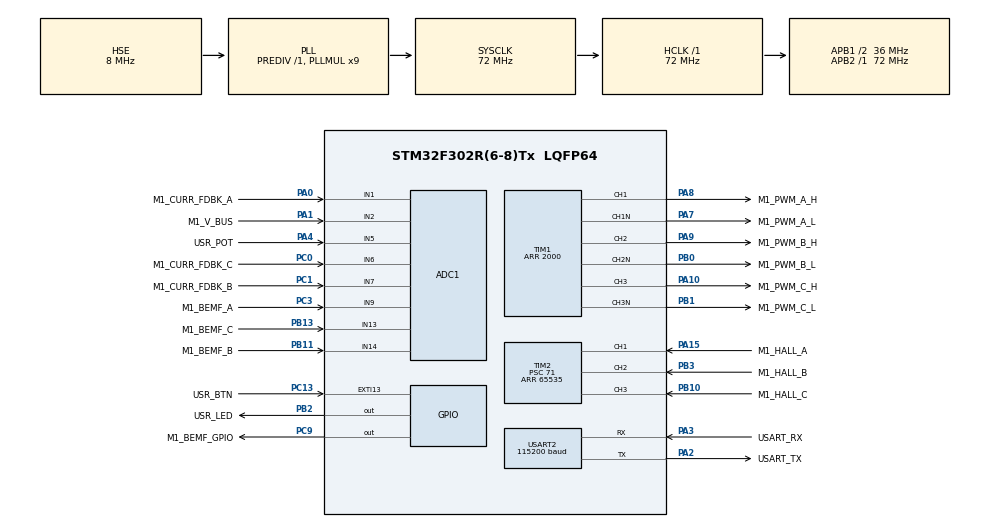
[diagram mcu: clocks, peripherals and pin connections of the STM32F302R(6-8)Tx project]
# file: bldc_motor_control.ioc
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ADC1.Channel-1\#ChannelRegularConversion=ADC_CHANNEL_9
ADC1.Channel-12\#ChannelRegularConversion=ADC_CHANNEL_6
ADC1.Channel-13\#ChannelRegularConversion=ADC_CHANNEL_2
ADC1.Channel-14\#ChannelRegularConversion=ADC_CHANNEL_5
ADC1.Channel-2\#ChannelRegularConversion=ADC_CHANNEL_14
ADC1.Channel-3\#ChannelRegularConversion=ADC_CHANNEL_13
ADC1.Channel-4\#ChannelRegularConversion=ADC_CHANNEL_1
ADC1.Channel-5\#ChannelRegularConversion=ADC_CHANNEL_7
ADC1.DMAContinuousRequests=ENABLE
ADC1.EOCSelection=ADC_EOC_SEQ_CONV
ADC1.EnableInjectedConversion=DISABLE
ADC1.ExternalTrigConv=ADC_EXTERNALTRIGCONV_T1_TRGO
ADC1.NbrOfConversion=8
ADC1.NbrOfConversionFlag=1
ADC1.Offset-1\#ChannelRegularConversion=0
ADC1.Offset-12\#ChannelRegularConversion=0
ADC1.Offset-13\#ChannelRegularConversion=0
ADC1.Offset-14\#ChannelRegularConversion=0
ADC1.Offset-2\#ChannelRegularConversion=0
ADC1.Offset-3\#ChannelRegularConversion=0
ADC1.Offset-4\#ChannelRegularConversion=0
ADC1.Offset-5\#ChannelRegularConversion=0
ADC1.OffsetNumber-1\#ChannelRegularConversion=ADC_OFFSET_NONE
ADC1.OffsetNumber-12\#ChannelRegularConversion=ADC_OFFSET_NONE
ADC1.OffsetNumber-13\#ChannelRegularConversion=ADC_OFFSET_NONE
ADC1.OffsetNumber-14\#ChannelRegularConversion=ADC_OFFSET_NONE
ADC1.OffsetNumber-2\#ChannelRegularConversion=ADC_OFFSET_NONE
ADC1.OffsetNumber-3\#ChannelRegularConversion=ADC_OFFSET_NONE
ADC1.OffsetNumber-4\#ChannelRegularConversion=ADC_OFFSET_NONE
ADC1.OffsetNumber-5\#ChannelRegularConversion=ADC_OFFSET_NONE
ADC1.Rank-1\#ChannelRegularConversion=1
ADC1.Rank-12\#ChannelRegularConversion=6
ADC1.Rank-13\#ChannelRegularConversion=7
ADC1.Rank-14\#ChannelRegularConversion=8
ADC1.Rank-2\#ChannelRegularConversion=2
ADC1.Rank-3\#ChannelRegularConversion=3
ADC1.Rank-4\#ChannelRegularConversion=4
ADC1.Rank-5\#ChannelRegularConversion=5
ADC1.Rank1_Channel=ADC_CHANNEL_9
ADC1.Rank2_Channel=ADC_CHANNEL_13
ADC1.Rank3_Channel=ADC_CHANNEL_14
ADC1.SamplingTime-1\#ChannelRegularConversion=ADC_SAMPLETIME_61CYCLES_5
ADC1.SamplingTime-12\#ChannelRegularConversion=ADC_SAMPLETIME_61CYCLES_5
ADC1.SamplingTime-13\#ChannelRegularConversion=ADC_SAMPLETIME_61CYCLES_5
ADC1.SamplingTime-14\#ChannelRegularConversion=ADC_SAMPLETIME_61CYCLES_5
ADC1.SamplingTime-2\#ChannelRegularConversion=ADC_SAMPLETIME_61CYCLES_5
ADC1.SamplingTime-3\#ChannelRegularConversion=ADC_SAMPLETIME_61CYCLES_5
ADC1.SamplingTime-4\#ChannelRegularConversion=ADC_SAMPLETIME_61CYCLES_5
ADC1.SamplingTime-5\#ChannelRegularConversion=ADC_SAMPLETIME_61CYCLES_5
ADC1.SamplingTimeOPAMP-12\#ChannelRegularConversion=ADC_SAMPLETIME_61CYCLES_5
ADC1.SamplingTimeOPAMP-13\#ChannelRegularConversion=ADC_SAMPLETIME_61CYCLES_5
ADC1.SamplingTimeOPAMP-14\#ChannelRegularConversion=ADC_SAMPLETIME_61CYCLES_5
ADC1.SamplingTimeOPAMP-2\#ChannelRegularConversion=ADC_SAMPLETIME_61CYCLES_5
ADC1.SamplingTimeOPAMP-3\#ChannelRegularConversion=ADC_SAMPLETIME_61CYCLES_5
ADC1.SamplingTimeOPAMP-4\#ChannelRegularConversion=ADC_SAMPLETIME_61CYCLES_5
ADC1.SamplingTimeOPAMP-5\#ChannelRegularConversion=ADC_SAMPLETIME_61CYCLES_5
ADC1.SubFamily=STM32F302x8
ADC1.master=1
Dma.ADC1.0.Direction=DMA_PERIPH_TO_MEMORY
Dma.ADC1.0.Instance=DMA1_Channel1
Dma.ADC1.0.MemDataAlignment=DMA_MDATAALIGN_WORD
Dma.ADC1.0.MemInc=DMA_MINC_ENABLE
Dma.ADC1.0.Mode=DMA_CIRCULAR
Dma.ADC1.0.PeriphDataAlignment=DMA_PDATAALIGN_WORD
Dma.ADC1.0.PeriphInc=DMA_PINC_DISABLE
Dma.ADC1.0.Priority=DMA_PRIORITY_LOW
Dma.Request0=ADC1
Mcu.Family=STM32F3
Mcu.Name=STM32F302R(6-8)Tx
Mcu.Package=LQFP64
NVIC.DMA1_Channel1_IRQn=true\:0\:0\:false\:false\:true\:false\:true\:true
NVIC.EXTI15_10_IRQn=true\:0\:0\:false\:false\:true\:true\:true\:true
NVIC.PriorityGroup=NVIC_PRIORITYGROUP_0
NVIC.TIM2_IRQn=true\:0\:0\:false\:false\:true\:true\:true\:true
PA0.GPIO_Label=M1_CURR_FDBK_A
PA0.Mode=IN1-Single-Ended
PA0.Signal=ADC1_IN1
PA1.GPIO_Label=M1_V_BUS
PA1.Mode=IN2-Single-Ended
PA1.Signal=ADC1_IN2
PA10.GPIO_Label=M1_PWM_C_H
PA10.Signal=S_TIM1_CH3
PA15.GPIO_Label=M1_HALL_A
PA15.Signal=S_TIM2_CH1_ETR
PA2.GPIO_Label=USART_TX
PA2.Mode=Asynchronous
PA2.Signal=USART2_TX
PA3.GPIO_Label=USART_RX
PA3.Mode=Asynchronous
PA3.Signal=USART2_RX
PA4.GPIO_Label=USR_POT
PA4.Mode=IN5-Single-Ended
PA4.Signal=ADC1_IN5
PA7.GPIO_Label=M1_PWM_A_L
PA7.Mode=PWM Generation1 CH1 CH1N
PA7.Signal=TIM1_CH1N
PA8.GPIO_Label=M1_PWM_A_H
PA8.Signal=S_TIM1_CH1
PA9.GPIO_Label=M1_PWM_B_H
PA9.Signal=S_TIM1_CH2
PB0.GPIO_Label=M1_PWM_B_L
PB0.Mode=PWM Generation2 CH2 CH2N
PB0.Signal=TIM1_CH2N
PB1.GPIO_Label=M1_PWM_C_L
PB1.Mode=PWM Generation3 CH3 CH3N
PB1.Signal=TIM1_CH3N
PB10.GPIO_Label=M1_HALL_C
PB10.Signal=S_TIM2_CH3
PB11.GPIO_Label=M1_BEMF_B
PB11.Mode=IN14-Single-Ended
PB11.Signal=ADC1_IN14
PB13.GPIO_Label=M1_BEMF_C
PB13.Mode=IN13-Single-Ended
PB13.Signal=ADC1_IN13
PB2.GPIO_Label=USR_LED
PB2.Signal=GPIO_Output
PB3.GPIO_Label=M1_HALL_B
PB3.Signal=S_TIM2_CH2
PC0.GPIO_Label=M1_CURR_FDBK_C
PC0.Signal=ADCx_IN6
PC1.GPIO_Label=M1_CURR_FDBK_B
PC1.Signal=ADCx_IN7
PC13.GPIO_Label=USR_BTN
PC13.GPIO_ModeDefaultEXTI=GPIO_MODE_IT_FALLING
PC13.Signal=GPXTI13
PC3.GPIO_Label=M1_BEMF_A
PC3.Signal=ADCx_IN9
PC9.GPIO_Label=M1_BEMF_GPIO
PC9.GPIO_PuPd=GPIO_PULLUP
PC9.Signal=GPIO_Output
PF0-OSC_IN.GPIO_Label=RCC_OSC_IN
PF0-OSC_IN.Mode=HSE-External-Clock-Source
PF0-OSC_IN.Signal=RCC_OSC_IN
ProjectManager.HeapSize=0x200
ProjectManager.StackSize=0x400
ProjectManager.TargetToolchain=CMake
RCC.AHBFreq_Value=72000000
RCC.APB1CLKDivider=RCC_HCLK_DIV2
RCC.APB1Freq_Value=36000000
RCC.APB1TimFreq_Value=72000000
RCC.APB2Freq_Value=72000000
RCC.APB2TimFreq_Value=72000000
RCC.CortexFreq_Value=72000000
RCC.HCLKFreq_Value=72000000
RCC.HSE_VALUE=8000000
RCC.HSI_VALUE=8000000
RCC.LSE_VALUE=32768
RCC.PLLM=8
RCC.PLLMUL=RCC_PLL_MUL9
RCC.PLLN=336
RCC.PLLP=RCC_PLLP_DIV4
RCC.PLLQ=7
RCC.PLLSourceVirtual=RCC_PLLSOURCE_HSE
RCC.SYSCLKFreq_VALUE=72000000
RCC.SYSCLKSourceVirtual=RCC_SYSCLKSOURCE_PLLCLK
RCC.USBFreq_Value=72000000
SH.ADCx_IN6.0=ADC1_IN6,IN6-Single-Ended
SH.ADCx_IN7.0=ADC1_IN7,IN7-Single-Ended
SH.ADCx_IN9.0=ADC1_IN9,IN9-Single-Ended
SH.S_TIM1_CH1.0=TIM1_CH1,PWM Generation1 CH1 CH1N
SH.S_TIM1_CH2.0=TIM1_CH2,PWM Generation2 CH2 CH2N
SH.S_TIM1_CH3.0=TIM1_CH3,PWM Generation3 CH3 CH3N
SH.S_TIM2_CH1_ETR.0=TIM2_CH1,Input_Capture1_from_TI1
SH.S_TIM2_CH2.0=TIM2_CH2,Input_Capture2_from_TI2
SH.S_TIM2_CH3.0=TIM2_CH3,Input_Capture3_from_TI3
TIM1.Channel-PWM\ Generation1\ CH1\ CH1N=TIM_CHANNEL_1
TIM1.Channel-PWM\ Generation2\ CH2\ CH2N=TIM_CHANNEL_2
TIM1.Channel-PWM\ Generation3\ CH3\ CH3N=TIM_CHANNEL_3
TIM1.CounterMode=TIM_COUNTERMODE_CENTERALIGNED1
TIM1.DeadTime=72
TIM1.OCIdleState_1=TIM_OCIDLESTATE_SET
TIM1.OCIdleState_2=TIM_OCIDLESTATE_SET
TIM1.OCIdleState_3=TIM_OCIDLESTATE_SET
TIM1.OCNPolarity_1=TIM_OCNPOLARITY_LOW
TIM1.OCNPolarity_2=TIM_OCNPOLARITY_LOW
TIM1.OCNPolarity_3=TIM_OCNPOLARITY_LOW
TIM1.Period=2000
TIM1.RepetitionCounter=1
TIM1.TIM_MasterOutputTrigger=TIM_TRGO_UPDATE
TIM2.Channel-Input_Capture1_from_TI1=TIM_CHANNEL_1
TIM2.Channel-Input_Capture2_from_TI2=TIM_CHANNEL_2
TIM2.Channel-Input_Capture3_from_TI3=TIM_CHANNEL_3
TIM2.Period=65535
TIM2.Prescaler=71
TIM2.TIM_MasterOutputTrigger=TIM_TRGO_UPDATE
USART2.BaudRate=115200
USART2.VirtualMode-Asynchronous=VM_ASYNC
board=NUCLEO-F302R8

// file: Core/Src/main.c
/* USER CODE BEGIN Header */
/**
  ******************************************************************************
  * @file           : main.c
  * @brief          : Main program body
  ******************************************************************************
  * @attention
  *
  * Copyright (c) 2024 STMicroelectronics.
  * All rights reserved.
  *
  * This software is licensed under terms that can be found in the LICENSE file
  * in the root directory of this software component.
  * If no LICENSE file comes with this software, it is provided AS-IS.
  *
  ******************************************************************************
  */
/* USER CODE END Header */
#include "main.h"

/* USER CODE BEGIN Includes */
#include "application.hpp"
/* USER CODE END Includes */

ADC_HandleTypeDef hadc1;
DMA_HandleTypeDef hdma_adc1;

TIM_HandleTypeDef htim1;
TIM_HandleTypeDef htim2;

UART_HandleTypeDef huart2;

void SystemClock_Config(void);
static void MX_GPIO_Init(void);
static void MX_DMA_Init(void);
static void MX_ADC1_Init(void);
static void MX_TIM1_Init(void);
static void MX_USART2_UART_Init(void);
static void MX_TIM2_Init(void);

int main(void)
{

  /* MCU Configuration--------------------------------------------------------*/

  /* Reset of all peripherals, Initializes the Flash interface and the Systick. */
  HAL_Init();

  /* Configure the system clock */
  SystemClock_Config();

  /* Initialize all configured peripherals */
  MX_GPIO_Init();
  MX_DMA_Init();
  MX_ADC1_Init();
  MX_TIM1_Init();
  MX_USART2_UART_Init();
  MX_TIM2_Init();
  /* USER CODE BEGIN 2 */
  setup();
  /* USER CODE END 2 */

  /* Infinite loop */
  while (1)
  {

    /* USER CODE BEGIN 3 */
	  loop();
  }
  /* USER CODE END 3 */
}

void SystemClock_Config(void)
{
  RCC_OscInitTypeDef RCC_OscInitStruct = {0};
  RCC_ClkInitTypeDef RCC_ClkInitStruct = {0};
  RCC_PeriphCLKInitTypeDef PeriphClkInit = {0};

  /** Initializes the RCC Oscillators according to the specified parameters
  * in the RCC_OscInitTypeDef structure.
  */
  RCC_OscInitStruct.OscillatorType = RCC_OSCILLATORTYPE_HSE;
  RCC_OscInitStruct.HSEState = RCC_HSE_BYPASS;
  RCC_OscInitStruct.HSEPredivValue = RCC_HSE_PREDIV_DIV1;
  RCC_OscInitStruct.HSIState = RCC_HSI_ON;
  RCC_OscInitStruct.PLL.PLLState = RCC_PLL_ON;
  RCC_OscInitStruct.PLL.PLLSource = RCC_PLLSOURCE_HSE;
  RCC_OscInitStruct.PLL.PLLMUL = RCC_PLL_MUL9;
  if (HAL_RCC_OscConfig(&RCC_OscInitStruct) != HAL_OK)
  {
    Error_Handler();
  }

  /** Initializes the CPU, AHB and APB buses clocks
  */
  RCC_ClkInitStruct.ClockType = RCC_CLOCKTYPE_HCLK|RCC_CLOCKTYPE_SYSCLK
                              |RCC_CLOCKTYPE_PCLK1|RCC_CLOCKTYPE_PCLK2;
  RCC_ClkInitStruct.SYSCLKSource = RCC_SYSCLKSOURCE_PLLCLK;
  RCC_ClkInitStruct.AHBCLKDivider = RCC_SYSCLK_DIV1;
  RCC_ClkInitStruct.APB1CLKDivider = RCC_HCLK_DIV2;
  RCC_ClkInitStruct.APB2CLKDivider = RCC_HCLK_DIV1;

  if (HAL_RCC_ClockConfig(&RCC_ClkInitStruct, FLASH_LATENCY_2) != HAL_OK)
  {
    Error_Handler();
  }
  PeriphClkInit.PeriphClockSelection = RCC_PERIPHCLK_TIM1|RCC_PERIPHCLK_ADC1;
  PeriphClkInit.Tim1ClockSelection = RCC_TIM1CLK_HCLK;
  PeriphClkInit.Adc1ClockSelection = RCC_ADC1PLLCLK_DIV1;

  if (HAL_RCCEx_PeriphCLKConfig(&PeriphClkInit) != HAL_OK)
  {
    Error_Handler();
  }
}

static void MX_ADC1_Init(void)
{

  ADC_ChannelConfTypeDef sConfig = {0};

  /** Common config
  */
  hadc1.Instance = ADC1;
  hadc1.Init.ClockPrescaler = ADC_CLOCK_ASYNC_DIV1;
  hadc1.Init.Resolution = ADC_RESOLUTION_12B;
  hadc1.Init.ScanConvMode = ADC_SCAN_ENABLE;
  hadc1.Init.ContinuousConvMode = DISABLE;
  hadc1.Init.DiscontinuousConvMode = DISABLE;
  hadc1.Init.ExternalTrigConvEdge = ADC_EXTERNALTRIGCONVEDGE_RISING;
  hadc1.Init.ExternalTrigConv = ADC_EXTERNALTRIGCONV_T1_TRGO;
  hadc1.Init.DataAlign = ADC_DATAALIGN_RIGHT;
  hadc1.Init.NbrOfConversion = 8;
  hadc1.Init.DMAContinuousRequests = ENABLE;
  hadc1.Init.EOCSelection = ADC_EOC_SEQ_CONV;
  hadc1.Init.LowPowerAutoWait = DISABLE;
  hadc1.Init.Overrun = ADC_OVR_DATA_OVERWRITTEN;
  if (HAL_ADC_Init(&hadc1) != HAL_OK)
  {
    Error_Handler();
  }

  /** Configure Regular Channel
  */
  sConfig.Channel = ADC_CHANNEL_1;
  sConfig.Rank = ADC_REGULAR_RANK_1;
  sConfig.SingleDiff = ADC_SINGLE_ENDED;
  sConfig.SamplingTime = ADC_SAMPLETIME_7CYCLES_5;
  sConfig.OffsetNumber = ADC_OFFSET_NONE;
  sConfig.Offset = 0;
  if (HAL_ADC_ConfigChannel(&hadc1, &sConfig) != HAL_OK)
  {
    Error_Handler();
  }

  /** Configure Regular Channel
  */
  sConfig.Channel = ADC_CHANNEL_2;
  sConfig.Rank = ADC_REGULAR_RANK_2;
  if (HAL_ADC_ConfigChannel(&hadc1, &sConfig) != HAL_OK)
  {
    Error_Handler();
  }

  /** Configure Regular Channel
  */
  sConfig.Channel = ADC_CHANNEL_5;
  sConfig.Rank = ADC_REGULAR_RANK_3;
  if (HAL_ADC_ConfigChannel(&hadc1, &sConfig) != HAL_OK)
  {
    Error_Handler();
  }

  /** Configure Regular Channel
  */
  sConfig.Channel = ADC_CHANNEL_6;
  sConfig.Rank = ADC_REGULAR_RANK_4;
  if (HAL_ADC_ConfigChannel(&hadc1, &sConfig) != HAL_OK)
  {
    Error_Handler();
  }

  /** Configure Regular Channel
  */
  sConfig.Channel = ADC_CHANNEL_7;
  sConfig.Rank = ADC_REGULAR_RANK_5;
  if (HAL_ADC_ConfigChannel(&hadc1, &sConfig) != HAL_OK)
  {
    Error_Handler();
  }

  /** Configure Regular Channel
  */
  sConfig.Channel = ADC_CHANNEL_9;
  sConfig.Rank = ADC_REGULAR_RANK_6;
  if (HAL_ADC_ConfigChannel(&hadc1, &sConfig) != HAL_OK)
  {
    Error_Handler();
  }

  /** Configure Regular Channel
  */
  sConfig.Channel = ADC_CHANNEL_13;
  sConfig.Rank = ADC_REGULAR_RANK_7;
  if (HAL_ADC_ConfigChannel(&hadc1, &sConfig) != HAL_OK)
  {
    Error_Handler();
  }

  /** Configure Regular Channel
  */
  sConfig.Channel = ADC_CHANNEL_14;
  sConfig.Rank = ADC_REGULAR_RANK_8;
  if (HAL_ADC_ConfigChannel(&hadc1, &sConfig) != HAL_OK)
  {
    Error_Handler();
  }

}

static void MX_TIM1_Init(void)
{

  TIM_ClockConfigTypeDef sClockSourceConfig = {0};
  TIM_MasterConfigTypeDef sMasterConfig = {0};
  TIM_OC_InitTypeDef sConfigOC = {0};
  TIM_BreakDeadTimeConfigTypeDef sBreakDeadTimeConfig = {0};

  htim1.Instance = TIM1;
  htim1.Init.Prescaler = 0;
  htim1.Init.CounterMode = TIM_COUNTERMODE_CENTERALIGNED1;
  htim1.Init.Period = 1999;
  htim1.Init.ClockDivision = TIM_CLOCKDIVISION_DIV1;
  htim1.Init.RepetitionCounter = 0;
  htim1.Init.AutoReloadPreload = TIM_AUTORELOAD_PRELOAD_DISABLE;
  if (HAL_TIM_Base_Init(&htim1) != HAL_OK)
  {
    Error_Handler();
  }
  sClockSourceConfig.ClockSource = TIM_CLOCKSOURCE_INTERNAL;
  if (HAL_TIM_ConfigClockSource(&htim1, &sClockSourceConfig) != HAL_OK)
  {
    Error_Handler();
  }
  if (HAL_TIM_PWM_Init(&htim1) != HAL_OK)
  {
    Error_Handler();
  }
  sMasterConfig.MasterOutputTrigger = TIM_TRGO_UPDATE;
  sMasterConfig.MasterOutputTrigger2 = TIM_TRGO2_RESET;
  sMasterConfig.MasterSlaveMode = TIM_MASTERSLAVEMODE_DISABLE;
  if (HAL_TIMEx_MasterConfigSynchronization(&htim1, &sMasterConfig) != HAL_OK)
  {
    Error_Handler();
  }
  sConfigOC.OCMode = TIM_OCMODE_PWM1;
  sConfigOC.Pulse = 0;
  sConfigOC.OCPolarity = TIM_OCPOLARITY_HIGH;
  sConfigOC.OCNPolarity = TIM_OCNPOLARITY_LOW;
  sConfigOC.OCFastMode = TIM_OCFAST_DISABLE;
  sConfigOC.OCIdleState = TIM_OCIDLESTATE_SET;
  sConfigOC.OCNIdleState = TIM_OCNIDLESTATE_RESET;
  if (HAL_TIM_PWM_ConfigChannel(&htim1, &sConfigOC, TIM_CHANNEL_1) != HAL_OK)
  {
    Error_Handler();
  }
  if (HAL_TIM_PWM_ConfigChannel(&htim1, &sConfigOC, TIM_CHANNEL_2) != HAL_OK)
  {
    Error_Handler();
  }
  if (HAL_TIM_PWM_ConfigChannel(&htim1, &sConfigOC, TIM_CHANNEL_3) != HAL_OK)
  {
    Error_Handler();
  }
  sBreakDeadTimeConfig.OffStateRunMode = TIM_OSSR_DISABLE;
  sBreakDeadTimeConfig.OffStateIDLEMode = TIM_OSSI_DISABLE;
  sBreakDeadTimeConfig.LockLevel = TIM_LOCKLEVEL_OFF;
  sBreakDeadTimeConfig.DeadTime = 0;
  sBreakDeadTimeConfig.BreakState = TIM_BREAK_DISABLE;
  sBreakDeadTimeConfig.BreakPolarity = TIM_BREAKPOLARITY_HIGH;
  sBreakDeadTimeConfig.BreakFilter = 0;
  sBreakDeadTimeConfig.Break2State = TIM_BREAK2_DISABLE;
  sBreakDeadTimeConfig.Break2Polarity = TIM_BREAK2POLARITY_HIGH;
  sBreakDeadTimeConfig.Break2Filter = 0;
  sBreakDeadTimeConfig.AutomaticOutput = TIM_AUTOMATICOUTPUT_DISABLE;
  if (HAL_TIMEx_ConfigBreakDeadTime(&htim1, &sBreakDeadTimeConfig) != HAL_OK)
  {
    Error_Handler();
  }
  HAL_TIM_MspPostInit(&htim1);

}

static void MX_TIM2_Init(void)
{

  TIM_ClockConfigTypeDef sClockSourceConfig = {0};
  TIM_MasterConfigTypeDef sMasterConfig = {0};
  TIM_IC_InitTypeDef sConfigIC = {0};

  htim2.Instance = TIM2;
  htim2.Init.Prescaler = 71;
  htim2.Init.CounterMode = TIM_COUNTERMODE_UP;
  htim2.Init.Period = 65535;
  htim2.Init.ClockDivision = TIM_CLOCKDIVISION_DIV1;
  htim2.Init.AutoReloadPreload = TIM_AUTORELOAD_PRELOAD_DISABLE;
  if (HAL_TIM_Base_Init(&htim2) != HAL_OK)
  {
    Error_Handler();
  }
  sClockSourceConfig.ClockSource = TIM_CLOCKSOURCE_INTERNAL;
  if (HAL_TIM_ConfigClockSource(&htim2, &sClockSourceConfig) != HAL_OK)
  {
    Error_Handler();
  }
  if (HAL_TIM_IC_Init(&htim2) != HAL_OK)
  {
    Error_Handler();
  }
  sMasterConfig.MasterOutputTrigger = TIM_TRGO_UPDATE;
  sMasterConfig.MasterSlaveMode = TIM_MASTERSLAVEMODE_DISABLE;
  if (HAL_TIMEx_MasterConfigSynchronization(&htim2, &sMasterConfig) != HAL_OK)
  {
    Error_Handler();
  }
  sConfigIC.ICPolarity = TIM_INPUTCHANNELPOLARITY_RISING;
  sConfigIC.ICSelection = TIM_ICSELECTION_DIRECTTI;
  sConfigIC.ICPrescaler = TIM_ICPSC_DIV1;
  sConfigIC.ICFilter = 0;
  if (HAL_TIM_IC_ConfigChannel(&htim2, &sConfigIC, TIM_CHANNEL_1) != HAL_OK)
  {
    Error_Handler();
  }
  if (HAL_TIM_IC_ConfigChannel(&htim2, &sConfigIC, TIM_CHANNEL_2) != HAL_OK)
  {
    Error_Handler();
  }
  if (HAL_TIM_IC_ConfigChannel(&htim2, &sConfigIC, TIM_CHANNEL_3) != HAL_OK)
  {
    Error_Handler();
  }

}

static void MX_USART2_UART_Init(void)
{

  huart2.Instance = USART2;
  huart2.Init.BaudRate = 115200;
  huart2.Init.WordLength = UART_WORDLENGTH_8B;
  huart2.Init.StopBits = UART_STOPBITS_1;
  huart2.Init.Parity = UART_PARITY_NONE;
  huart2.Init.Mode = UART_MODE_TX_RX;
  huart2.Init.HwFlowCtl = UART_HWCONTROL_NONE;
  huart2.Init.OverSampling = UART_OVERSAMPLING_16;
  huart2.Init.OneBitSampling = UART_ONE_BIT_SAMPLE_DISABLE;
  huart2.AdvancedInit.AdvFeatureInit = UART_ADVFEATURE_NO_INIT;
  if (HAL_UART_Init(&huart2) != HAL_OK)
  {
    Error_Handler();
  }

}

static void MX_DMA_Init(void)
{

  /* DMA controller clock enable */
  __HAL_RCC_DMA1_CLK_ENABLE();

  /* DMA interrupt init */
  /* DMA1_Channel1_IRQn interrupt configuration */
  HAL_NVIC_SetPriority(DMA1_Channel1_IRQn, 0, 0);
  HAL_NVIC_EnableIRQ(DMA1_Channel1_IRQn);

}

static void MX_GPIO_Init(void)
{
  GPIO_InitTypeDef GPIO_InitStruct = {0};

  /* GPIO Ports Clock Enable */
  __HAL_RCC_GPIOC_CLK_ENABLE();
  __HAL_RCC_GPIOF_CLK_ENABLE();
  __HAL_RCC_GPIOA_CLK_ENABLE();
  __HAL_RCC_GPIOB_CLK_ENABLE();

  /*Configure GPIO pin Output Level */
  HAL_GPIO_WritePin(USR_LED_GPIO_Port, USR_LED_Pin, GPIO_PIN_RESET);

  /*Configure GPIO pin Output Level */
  HAL_GPIO_WritePin(M1_BEMF_GPIO_GPIO_Port, M1_BEMF_GPIO_Pin, GPIO_PIN_RESET);

  /*Configure GPIO pin : USR_BTN_Pin */
  GPIO_InitStruct.Pin = USR_BTN_Pin;
  GPIO_InitStruct.Mode = GPIO_MODE_IT_FALLING;
  GPIO_InitStruct.Pull = GPIO_NOPULL;
  HAL_GPIO_Init(USR_BTN_GPIO_Port, &GPIO_InitStruct);

  /*Configure GPIO pin : USR_LED_Pin */
  GPIO_InitStruct.Pin = USR_LED_Pin;
  GPIO_InitStruct.Mode = GPIO_MODE_OUTPUT_PP;
  GPIO_InitStruct.Pull = GPIO_NOPULL;
  GPIO_InitStruct.Speed = GPIO_SPEED_FREQ_LOW;
  HAL_GPIO_Init(USR_LED_GPIO_Port, &GPIO_InitStruct);

  /*Configure GPIO pin : M1_BEMF_GPIO_Pin */
  GPIO_InitStruct.Pin = M1_BEMF_GPIO_Pin;
  GPIO_InitStruct.Mode = GPIO_MODE_OUTPUT_PP;
  GPIO_InitStruct.Pull = GPIO_PULLUP;
  GPIO_InitStruct.Speed = GPIO_SPEED_FREQ_LOW;
  HAL_GPIO_Init(M1_BEMF_GPIO_GPIO_Port, &GPIO_InitStruct);

  /* EXTI interrupt init*/
  HAL_NVIC_SetPriority(EXTI15_10_IRQn, 0, 0);
  HAL_NVIC_EnableIRQ(EXTI15_10_IRQn);

}

void Error_Handler(void)
{
  __disable_irq();
  while (1)
  {
  }
}
